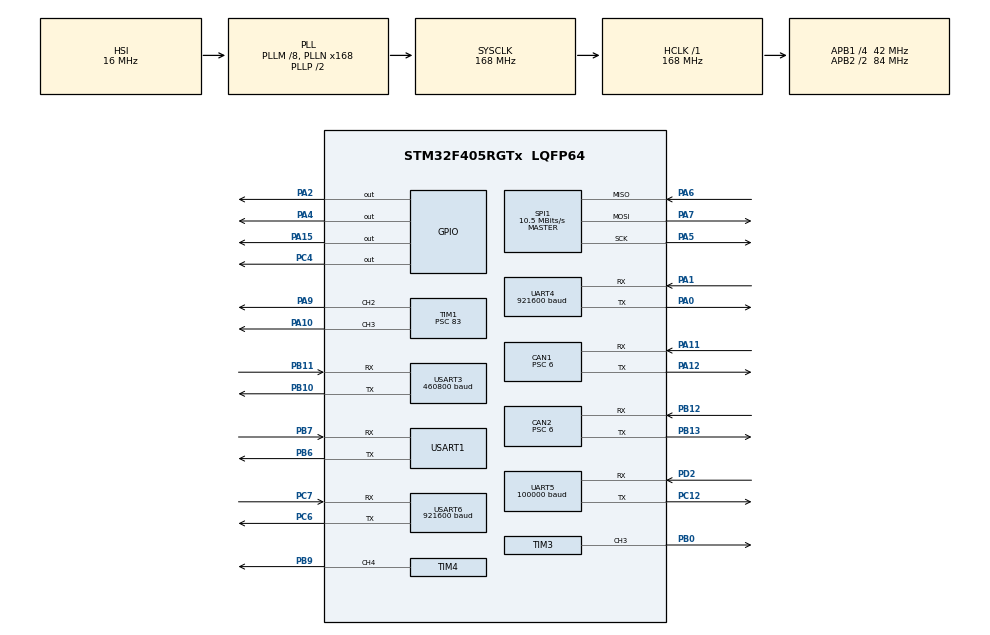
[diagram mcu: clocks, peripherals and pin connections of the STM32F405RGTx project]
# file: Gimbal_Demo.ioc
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CAN1.ABOM=ENABLE
CAN1.BS1=CAN_BS1_4TQ
CAN1.BS2=CAN_BS2_2TQ
CAN1.CalculateBaudRate=1000000
CAN1.CalculateTimeBit=1000
CAN1.CalculateTimeQuantum=142.85714285714286
CAN1.NART=ENABLE
CAN1.Prescaler=6
CAN2.ABOM=ENABLE
CAN2.BS1=CAN_BS1_4TQ
CAN2.BS2=CAN_BS2_2TQ
CAN2.CalculateBaudRate=1000000
CAN2.CalculateTimeBit=1000
CAN2.CalculateTimeQuantum=142.85714285714286
CAN2.NART=ENABLE
CAN2.Prescaler=6
Dma.Request0=USART6_RX
Dma.Request1=UART4_RX
Dma.Request2=USART3_RX
Dma.Request3=USART3_TX
Dma.Request4=UART5_RX
Dma.Request5=TIM4_UP
Dma.Request6=TIM3_CH3
Dma.TIM3_CH3.6.Direction=DMA_MEMORY_TO_PERIPH
Dma.TIM3_CH3.6.FIFOMode=DMA_FIFOMODE_DISABLE
Dma.TIM3_CH3.6.Instance=DMA1_Stream7
Dma.TIM3_CH3.6.MemDataAlignment=DMA_MDATAALIGN_HALFWORD
Dma.TIM3_CH3.6.MemInc=DMA_MINC_ENABLE
Dma.TIM3_CH3.6.Mode=DMA_CIRCULAR
Dma.TIM3_CH3.6.PeriphDataAlignment=DMA_PDATAALIGN_HALFWORD
Dma.TIM3_CH3.6.PeriphInc=DMA_PINC_DISABLE
Dma.TIM3_CH3.6.Priority=DMA_PRIORITY_LOW
Dma.TIM4_UP.5.Direction=DMA_MEMORY_TO_PERIPH
Dma.TIM4_UP.5.FIFOMode=DMA_FIFOMODE_DISABLE
Dma.TIM4_UP.5.Instance=DMA1_Stream6
Dma.TIM4_UP.5.MemDataAlignment=DMA_MDATAALIGN_HALFWORD
Dma.TIM4_UP.5.MemInc=DMA_MINC_ENABLE
Dma.TIM4_UP.5.Mode=DMA_CIRCULAR
Dma.TIM4_UP.5.PeriphDataAlignment=DMA_PDATAALIGN_HALFWORD
Dma.TIM4_UP.5.PeriphInc=DMA_PINC_DISABLE
Dma.TIM4_UP.5.Priority=DMA_PRIORITY_VERY_HIGH
Dma.UART4_RX.1.Direction=DMA_PERIPH_TO_MEMORY
Dma.UART4_RX.1.FIFOMode=DMA_FIFOMODE_DISABLE
Dma.UART4_RX.1.Instance=DMA1_Stream2
Dma.UART4_RX.1.MemDataAlignment=DMA_MDATAALIGN_BYTE
Dma.UART4_RX.1.MemInc=DMA_MINC_ENABLE
Dma.UART4_RX.1.Mode=DMA_NORMAL
Dma.UART4_RX.1.PeriphDataAlignment=DMA_PDATAALIGN_BYTE
Dma.UART4_RX.1.PeriphInc=DMA_PINC_DISABLE
Dma.UART4_RX.1.Priority=DMA_PRIORITY_VERY_HIGH
Dma.UART5_RX.4.Direction=DMA_PERIPH_TO_MEMORY
Dma.UART5_RX.4.FIFOMode=DMA_FIFOMODE_DISABLE
Dma.UART5_RX.4.Instance=DMA1_Stream0
Dma.UART5_RX.4.MemDataAlignment=DMA_MDATAALIGN_BYTE
Dma.UART5_RX.4.MemInc=DMA_MINC_ENABLE
Dma.UART5_RX.4.Mode=DMA_NORMAL
Dma.UART5_RX.4.PeriphDataAlignment=DMA_PDATAALIGN_BYTE
Dma.UART5_RX.4.PeriphInc=DMA_PINC_DISABLE
Dma.UART5_RX.4.Priority=DMA_PRIORITY_LOW
Dma.USART3_RX.2.Direction=DMA_PERIPH_TO_MEMORY
Dma.USART3_RX.2.FIFOMode=DMA_FIFOMODE_DISABLE
Dma.USART3_RX.2.Instance=DMA1_Stream1
Dma.USART3_RX.2.MemDataAlignment=DMA_MDATAALIGN_BYTE
Dma.USART3_RX.2.MemInc=DMA_MINC_ENABLE
Dma.USART3_RX.2.Mode=DMA_NORMAL
Dma.USART3_RX.2.PeriphDataAlignment=DMA_PDATAALIGN_BYTE
Dma.USART3_RX.2.PeriphInc=DMA_PINC_DISABLE
Dma.USART3_RX.2.Priority=DMA_PRIORITY_VERY_HIGH
Dma.USART3_TX.3.Direction=DMA_MEMORY_TO_PERIPH
Dma.USART3_TX.3.FIFOMode=DMA_FIFOMODE_DISABLE
Dma.USART3_TX.3.Instance=DMA1_Stream3
Dma.USART3_TX.3.MemDataAlignment=DMA_MDATAALIGN_BYTE
Dma.USART3_TX.3.MemInc=DMA_MINC_ENABLE
Dma.USART3_TX.3.Mode=DMA_NORMAL
Dma.USART3_TX.3.PeriphDataAlignment=DMA_PDATAALIGN_BYTE
Dma.USART3_TX.3.PeriphInc=DMA_PINC_DISABLE
Dma.USART3_TX.3.Priority=DMA_PRIORITY_VERY_HIGH
Dma.USART6_RX.0.Direction=DMA_PERIPH_TO_MEMORY
Dma.USART6_RX.0.FIFOMode=DMA_FIFOMODE_DISABLE
Dma.USART6_RX.0.Instance=DMA2_Stream1
Dma.USART6_RX.0.MemDataAlignment=DMA_MDATAALIGN_BYTE
Dma.USART6_RX.0.MemInc=DMA_MINC_ENABLE
Dma.USART6_RX.0.Mode=DMA_NORMAL
Dma.USART6_RX.0.PeriphDataAlignment=DMA_PDATAALIGN_BYTE
Dma.USART6_RX.0.PeriphInc=DMA_PINC_DISABLE
Dma.USART6_RX.0.Priority=DMA_PRIORITY_HIGH
Mcu.Family=STM32F4
Mcu.Name=STM32F405RGTx
Mcu.Package=LQFP64
NVIC.CAN1_RX0_IRQn=true\:3\:0\:true\:false\:true\:true\:true\:true
NVIC.CAN2_RX1_IRQn=true\:0\:0\:false\:false\:true\:true\:true\:true
NVIC.DMA1_Stream0_IRQn=true\:0\:0\:false\:false\:true\:false\:true\:true
NVIC.DMA1_Stream1_IRQn=true\:0\:0\:false\:false\:true\:false\:true\:true
NVIC.DMA1_Stream2_IRQn=true\:0\:0\:false\:false\:true\:false\:true\:true
NVIC.DMA1_Stream3_IRQn=true\:0\:0\:false\:false\:true\:false\:true\:true
NVIC.DMA1_Stream6_IRQn=true\:0\:0\:false\:false\:true\:false\:true\:true
NVIC.DMA1_Stream7_IRQn=true\:0\:0\:false\:false\:true\:false\:true\:true
NVIC.DMA2_Stream1_IRQn=true\:0\:0\:false\:false\:true\:false\:true\:true
NVIC.PriorityGroup=NVIC_PRIORITYGROUP_4
NVIC.TIM1_BRK_TIM9_IRQn=true\:0\:0\:false\:false\:true\:true\:true\:true
NVIC.TIM1_UP_TIM10_IRQn=true\:7\:0\:true\:false\:true\:true\:true\:true
NVIC.TIM4_IRQn=true\:0\:0\:false\:false\:true\:true\:true\:true
NVIC.TIM5_IRQn=true\:0\:0\:false\:false\:true\:true\:true\:true
NVIC.TIM6_DAC_IRQn=true\:10\:0\:true\:false\:true\:true\:true\:true
NVIC.TIM7_IRQn=true\:7\:0\:true\:false\:true\:true\:true\:true
NVIC.TIM8_BRK_TIM12_IRQn=true\:4\:0\:true\:false\:true\:true\:true\:true
NVIC.TIM8_UP_TIM13_IRQn=true\:6\:0\:true\:false\:true\:true\:true\:true
NVIC.UART4_IRQn=true\:0\:0\:false\:false\:true\:true\:true\:true
NVIC.UART5_IRQn=true\:0\:0\:false\:false\:true\:true\:true\:true
NVIC.USART1_IRQn=true\:0\:0\:false\:false\:true\:true\:true\:true
NVIC.USART3_IRQn=true\:0\:0\:false\:false\:true\:true\:true\:true
NVIC.USART6_IRQn=true\:0\:0\:false\:false\:true\:true\:true\:true
PA0-WKUP.GPIO_PuPd=GPIO_PULLUP
PA0-WKUP.Mode=Asynchronous
PA0-WKUP.Signal=UART4_TX
PA1.GPIO_PuPd=GPIO_PULLUP
PA1.Mode=Asynchronous
PA1.Signal=UART4_RX
PA10.GPIO_ModeDefaultPP=GPIO_MODE_AF_PP
PA10.GPIO_PuPd=GPIO_NOPULL
PA10.Signal=S_TIM1_CH3
PA11.Mode=CAN_Activate
PA11.Signal=CAN1_RX
PA12.Mode=CAN_Activate
PA12.Signal=CAN1_TX
PA13.Mode=Serial_Wire
PA13.Signal=SYS_JTMS-SWDIO
PA14.Mode=Serial_Wire
PA14.Signal=SYS_JTCK-SWCLK
PA15.Signal=GPIO_Output
PA2.GPIO_PuPd=GPIO_PULLDOWN
PA2.Signal=GPIO_Output
PA4.Signal=GPIO_Output
PA5.Mode=Full_Duplex_Master
PA5.Signal=SPI1_SCK
PA6.Mode=Full_Duplex_Master
PA6.Signal=SPI1_MISO
PA7.Mode=Full_Duplex_Master
PA7.Signal=SPI1_MOSI
PA9.Signal=S_TIM1_CH2
PB0.Signal=S_TIM3_CH3
PB10.GPIO_PuPd=GPIO_PULLUP
PB10.Mode=Asynchronous
PB10.Signal=USART3_TX
PB11.GPIO_PuPd=GPIO_PULLUP
PB11.Mode=Asynchronous
PB11.Signal=USART3_RX
PB12.Mode=CAN_Activate
PB12.Signal=CAN2_RX
PB13.Mode=CAN_Activate
PB13.Signal=CAN2_TX
PB6.GPIO_PuPd=GPIO_PULLUP
PB6.Mode=Asynchronous
PB6.Signal=USART1_TX
PB7.GPIO_PuPd=GPIO_PULLUP
PB7.Mode=Asynchronous
PB7.Signal=USART1_RX
PB9.Signal=S_TIM4_CH4
PC12.GPIO_PuPd=GPIO_PULLUP
PC12.Mode=Asynchronous
PC12.Signal=UART5_TX
PC4.Signal=GPIO_Output
PC6.GPIO_PuPd=GPIO_PULLUP
PC6.Mode=Asynchronous
PC6.Signal=USART6_TX
PC7.GPIO_PuPd=GPIO_PULLUP
PC7.Mode=Asynchronous
PC7.Signal=USART6_RX
PD2.GPIO_PuPd=GPIO_PULLUP
PD2.Mode=Asynchronous
PD2.Signal=UART5_RX
PH0-OSC_IN.Mode=HSE-External-Oscillator
PH0-OSC_IN.Signal=RCC_OSC_IN
PH1-OSC_OUT.Mode=HSE-External-Oscillator
PH1-OSC_OUT.Signal=RCC_OSC_OUT
ProjectManager.HeapSize=0x200
ProjectManager.StackSize=0x400
ProjectManager.TargetToolchain=MDK-ARM V5.32
RCC.48MHZClocksFreq_Value=84000000
RCC.AHBFreq_Value=168000000
RCC.APB1CLKDivider=RCC_HCLK_DIV4
RCC.APB1Freq_Value=42000000
RCC.APB1TimFreq_Value=84000000
RCC.APB2CLKDivider=RCC_HCLK_DIV2
RCC.APB2Freq_Value=84000000
RCC.APB2TimFreq_Value=168000000
RCC.CortexFreq_Value=168000000
RCC.HCLKFreq_Value=168000000
RCC.HSE_VALUE=25000000
RCC.HSI_VALUE=16000000
RCC.LSE_VALUE=32768
RCC.PLLM=8
RCC.PLLN=168
RCC.SYSCLKFreq_VALUE=168000000
RCC.SYSCLKSource=RCC_SYSCLKSOURCE_PLLCLK
RCC.VCOOutputFreq_Value=336000000
SH.S_TIM1_CH2.0=TIM1_CH2,PWM Generation2 CH2
SH.S_TIM1_CH3.0=TIM1_CH3,PWM Generation3 CH3
SH.S_TIM3_CH3.0=TIM3_CH3,PWM Generation3 CH3
SH.S_TIM4_CH4.0=TIM4_CH4,PWM Generation4 CH4
SPI1.BaudRatePrescaler=SPI_BAUDRATEPRESCALER_8
SPI1.CalculateBaudRate=10.5 MBits/s
SPI1.Direction=SPI_DIRECTION_2LINES
SPI1.Mode=SPI_MODE_MASTER
SPI1.VirtualType=VM_MASTER
TIM1.Channel-PWM\ Generation2\ CH2=TIM_CHANNEL_2
TIM1.Channel-PWM\ Generation3\ CH3=TIM_CHANNEL_3
TIM1.Period=20000-1
TIM1.Prescaler=83
TIM12.Period=100-1
TIM12.Prescaler=840-1
TIM3.Channel-PWM\ Generation3\ CH3=TIM_CHANNEL_3
TIM3.Period=105-1
TIM4.Channel-PWM\ Generation4\ CH4=TIM_CHANNEL_4
TIM4.Period=105-1
TIM5.Period=125-1
TIM5.Prescaler=840-1
TIM6.Period=10000-1
TIM6.Prescaler=840-1
TIM7.Period=400-1
TIM7.Prescaler=840-1
TIM8.Period=5000-1
TIM8.Prescaler=840-1
TIM9.Period=50-1
TIM9.Prescaler=1680-1
UART4.BaudRate=921600
UART4.VirtualMode=Asynchronous
UART5.BaudRate=100000
UART5.VirtualMode=Asynchronous
UART5.WordLength=WORDLENGTH_9B
USART1.VirtualMode=VM_ASYNC
USART3.BaudRate=460800
USART3.VirtualMode=VM_ASYNC
USART6.BaudRate=921600
USART6.VirtualMode=VM_ASYNC
USART6.WordLength=WORDLENGTH_8B
VP_TIM11_VS_ClockSourceINT.Mode=Enable_Timer
VP_TIM12_VS_ClockSourceINT.Mode=Internal
VP_TIM1_VS_ClockSourceINT.Mode=Internal
VP_TIM3_VS_ClockSourceINT.Mode=Internal
VP_TIM4_VS_ClockSourceINT.Mode=Internal
VP_TIM5_VS_ClockSourceINT.Mode=Internal
VP_TIM6_VS_ClockSourceINT.Mode=Enable_Timer
VP_TIM7_VS_ClockSourceINT.Mode=Enable_Timer
VP_TIM8_VS_ClockSourceINT.Mode=Internal
VP_TIM9_VS_ClockSourceINT.Mode=Internal
board=custom

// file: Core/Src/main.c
/* USER CODE BEGIN Header */
/**
 ******************************************************************************
 * @file           : main.c
 * @brief          : Main program body
 ******************************************************************************
 * @attention
 *
 * Copyright (c) 2025 STMicroelectronics.
 * All rights reserved.
 *
 * This software is licensed under terms that can be found in the LICENSE file
 * in the root directory of this software component.
 * If no LICENSE file comes with this software, it is provided AS-IS.
 *
 ******************************************************************************
 */
/* USER CODE END Header */
#include "main.h"
#include "can.h"
#include "dma.h"
#include "spi.h"
#include "tim.h"
#include "usart.h"
#include "gpio.h"

/* USER CODE BEGIN Includes */
#include "my_main.h"
/* USER CODE END Includes */

/* USER CODE BEGIN PV */
extern uint8_t bb;
extern uint8_t uart4_recbuf[32];
/* USER CODE END PV */

void SystemClock_Config(void);

int main(void)
{

  /* MCU Configuration--------------------------------------------------------*/

  /* Reset of all peripherals, Initializes the Flash interface and the Systick. */
  HAL_Init();

  /* Configure the system clock */
  SystemClock_Config();

  /* Initialize all configured peripherals */
  MX_GPIO_Init();
  MX_DMA_Init();
  MX_TIM7_Init();
  MX_USART3_UART_Init();
  MX_USART6_UART_Init();
  MX_CAN1_Init();
  MX_CAN2_Init();
  MX_TIM1_Init();
  MX_TIM9_Init();
  MX_USART1_UART_Init();
  MX_TIM12_Init();
  MX_TIM6_Init();
  MX_UART4_Init();
  MX_TIM8_Init();
  MX_UART5_Init();
  MX_SPI1_Init();
  MX_TIM4_Init();
  MX_TIM3_Init();
  MX_TIM11_Init();
  MX_TIM5_Init();
  /* USER CODE BEGIN 2 */
  My_Setup();
  /* USER CODE END 2 */

  /* Infinite loop */
  /* USER CODE BEGIN
	ILE */
  while (1)
  {
    My_Loop();
    /* USER CODE END WHILE */

  }
}

void SystemClock_Config(void)
{
  RCC_OscInitTypeDef RCC_OscInitStruct = {0};
  RCC_ClkInitTypeDef RCC_ClkInitStruct = {0};

  /** Configure the main internal regulator output voltage
  */
  __HAL_RCC_PWR_CLK_ENABLE();
  __HAL_PWR_VOLTAGESCALING_CONFIG(PWR_REGULATOR_VOLTAGE_SCALE1);

  /** Initializes the RCC Oscillators according to the specified parameters
  * in the RCC_OscInitTypeDef structure.
  */
  RCC_OscInitStruct.OscillatorType = RCC_OSCILLATORTYPE_HSI;
  RCC_OscInitStruct.HSIState = RCC_HSI_ON;
  RCC_OscInitStruct.HSICalibrationValue = RCC_HSICALIBRATION_DEFAULT;
  RCC_OscInitStruct.PLL.PLLState = RCC_PLL_ON;
  RCC_OscInitStruct.PLL.PLLSource = RCC_PLLSOURCE_HSI;
  RCC_OscInitStruct.PLL.PLLM = 8;
  RCC_OscInitStruct.PLL.PLLN = 168;
  RCC_OscInitStruct.PLL.PLLP = RCC_PLLP_DIV2;
  RCC_OscInitStruct.PLL.PLLQ = 4;
  if (HAL_RCC_OscConfig(&RCC_OscInitStruct) != HAL_OK)
  {
    Error_Handler();
  }

  /** Initializes the CPU, AHB and APB buses clocks
  */
  RCC_ClkInitStruct.ClockType = RCC_CLOCKTYPE_HCLK|RCC_CLOCKTYPE_SYSCLK
                              |RCC_CLOCKTYPE_PCLK1|RCC_CLOCKTYPE_PCLK2;
  RCC_ClkInitStruct.SYSCLKSource = RCC_SYSCLKSOURCE_PLLCLK;
  RCC_ClkInitStruct.AHBCLKDivider = RCC_SYSCLK_DIV1;
  RCC_ClkInitStruct.APB1CLKDivider = RCC_HCLK_DIV4;
  RCC_ClkInitStruct.APB2CLKDivider = RCC_HCLK_DIV2;

  if (HAL_RCC_ClockConfig(&RCC_ClkInitStruct, FLASH_LATENCY_5) != HAL_OK)
  {
    Error_Handler();
  }
}

void Error_Handler(void)
{
  __disable_irq();
  while (1)
  {
  }
}

#ifdef  USE_FULL_ASSERT
/**
  * @brief  Reports the name of the source file and the source line number
  *         where the assert_param error has occurred.
  * @param  file: pointer to the source file name
  * @param  line: assert_param error line source number
  * @retval None
  */
void assert_failed(uint8_t *file, uint32_t line)
{
  /* USER CODE BEGIN 6 */
  /* User can add his own implementation to report the file name and line
     number, ex: printf("Wrong parameters value: file %s on line %d\r\n", file,
     line) */
  /* USER CODE END 6 */
}
#endif /* USE_FULL_ASSERT */
